# dm648_cslr_memprot_L1D_001 register map
Vendor: Texas Instruments
Peripheral module from a debugger description file.
Registers are 32-bit, access not given, reset 0xC0 unless marked. A register's access mark holds for its fields unless they carry their own. Offsets are as the file gives them; lines under a group give offsets from that group; [hi:lo] are bit positions; {n}, {i} and the like mark numbered series; 'fields as' and 'values as' point back to an identical list; <NAME> marks a mode.

## MEMPROTL1D — Memory Protection for L1D
0x00 MPFAR rw reset 0x0 — L1D Memory Protection Fault Address Reg
  [31:0] ADDR — L1D Fault Address
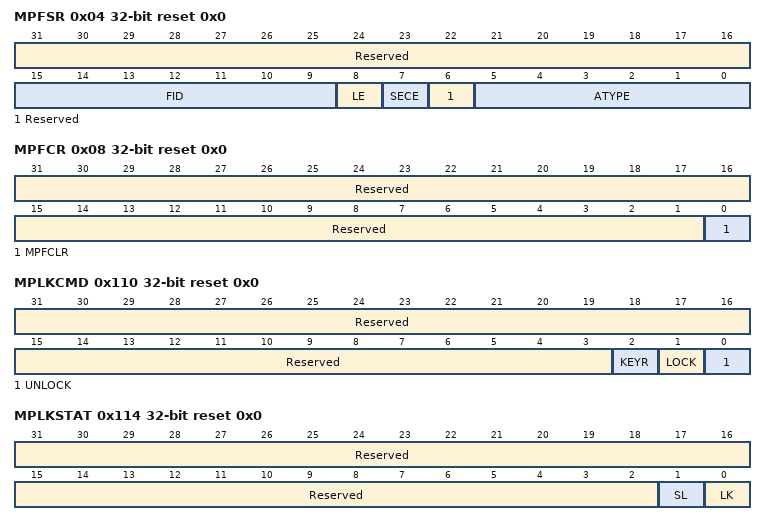
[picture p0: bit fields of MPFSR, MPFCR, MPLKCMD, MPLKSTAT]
0x04 MPFSR reset 0x0 — L1D Memory Protection Fault Status Reg
  [31:16] Reserved — (access N)
  [15:9] FID — ID of Faulting Access (access RC)
    1=FAULT (Fault Occurred); 0=OK (No Fault Occurred)
  [8] LE — Fault Due to Local Access (access RC)
  [7] SECE — Security Error (access RC)
    1=FAULT (Fault Occurred); 0=OK (No Fault Occurred)
  [6] Reserved — (access N)
  [5:0] ATYPE — Fault Access Type (access RC)
0x08 MPFCR reset 0x0 — L1D Memory Fault Clear Register
  [31:1] Reserved — (access N)
  [0] MPFCLR wo — Set to clear fault
    1=CLEAR (Clears Fault)
{0x100+4i} MPLK{i} reset 0x0 (i=0..3) — L1D Memory Protection Lock Key bits {32i+31}:{32i}
  [31:0] Reserved — (access N)
0x110 MPLKCMD reset 0x0 — L1D Memory Protection Lock Key Command Register
  [31:3] Reserved — (access N)
  [2] KEYR wo — Key Reset Field
    1=YES (Assert Key Reset - Only Supervisor May do this); 0=NO (Do Not Assert Key Reset)
  [1] LOCK wo — Lock Key Field
    1=YES (Assert Lock Bit - Correct Locking Sequence Must be followed); 0=NO (Do Not Assert Lock Bit)
  [0] UNLOCK wo — Unlock Key Field
    1=YES (Assert Unlock Bit - Correct Unlocking Sequence Must be followed to unlock Key); 0=NO (Do Not Assert Unlock Bit)
0x114 MPLKSTAT reset 0x0 — L1D Memory Protection Lock Key Status Register
  [31:2] Reserved — (access N)
  [1] SL ro — Security Level of Lock
    1=SEC (Security Level of Lock - Secure); 0=NONSEC (Security Level of Lock - Non-Secure)
  [0] LK ro — Lock Status
    1=YES (Lock is engaged); 0=NO (Lock is not engaged)
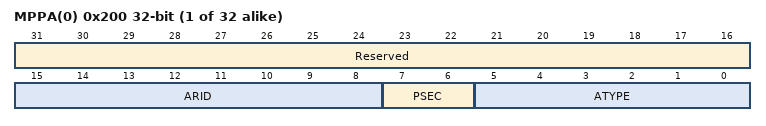
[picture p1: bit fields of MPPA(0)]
{0x200+4i} MPPA({i}) (reset mask 0xFFFF00C0) (i=0..31) — L1D Memory Protection Page Attribute Register
  [31:16] Reserved — (access N)
  [15:8] ARID rw — Allowed Requestor ID Access - Resetval Assumes Not Secure (pin driven) Secure would be 1
  [7:6] PSEC rw — Page Security Bits - Not Secure and EMU Secure - Default Assumes Not Secure (pin driven) - Secure would be 0
    0=SECNOEMU (Secure and No Emu access); 1=SECEMU (Secure with EMU access allowed); 3=SEC (Secure)
  [5:0] ATYPE rw — Access Types Allowed - Default Assumes Not Secure (pin driven) - Secure would be 56
